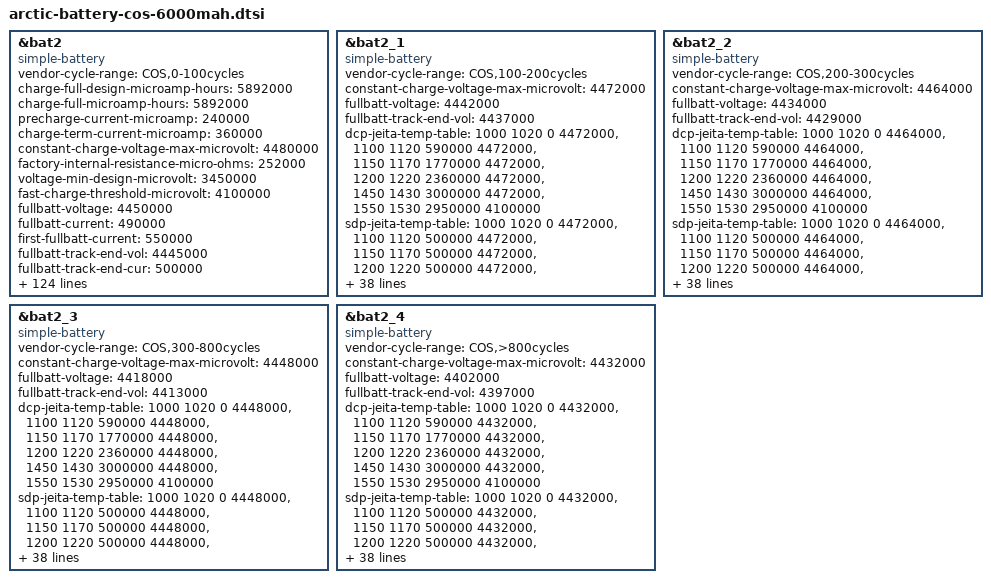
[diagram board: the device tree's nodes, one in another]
/* COS aging 0--100 */
&bat2 {
	compatible = "simple-battery";
	status = "okay";
	vendor-cycle-range = "COS,0-100cycles";
	charge-full-design-microamp-hours = <5892000>;
	charge-full-microamp-hours = <5892000>;
	precharge-current-microamp = <240000>;
	charge-term-current-microamp = <360000>;
	constant-charge-voltage-max-microvolt = <4480000>;
	factory-internal-resistance-micro-ohms = <252000>;
	voltage-min-design-microvolt = <3450000>;

	fast-charge-threshold-microvolt = <4100000>;
	fullbatt-voltage = <4450000>;
	fullbatt-current = <490000>;
	first-fullbatt-current = <550000>;
	fullbatt-track-end-vol = <4445000>;
	fullbatt-track-end-cur = <500000>;
	first-calib-voltage = <3580000>;
	first-calib-capacity = <50>;
	batt-ovp-threshold-microvolt = <4750000>;
	shutdown-voltage = <3150000>; //软件UVLO关机电压

	voltage-temp-table = <1119814 800>, <1007626 850>, <897107 900>,
				<791150 950>, <692012 1000>, <601214 1050>,
				<519546 1100>, <447188 1150>, <383853 1200>,
				<328947 1250>, <281696 1300>, <241249 1350>,
				<206756 1400>, <177412 1450>, <152480 1500>,
				<131307 1550>, <113324 1600>, <98032 1650>;

	temp-advance-fullcap-table = <50 100>, <25 100>, <10 100>, <0 100>,
		<(-10) 100>, <(-20) 100>;

	bcl-vbat-thres-celsius = <(-10)>, <0>, <10>, <25>, <45>;
	bcl-vbat-h-thres-0 = <3500>, <3400>;
	bcl-vbat-l-thres-0 = <3300>, <3200>;
	bcl-vbat-h-thres-1 = <3500>, <3400>;
	bcl-vbat-l-thres-1 = <3300>, <3200>;
	bcl-vbat-h-thres-2 = <3500>, <3400>;
	bcl-vbat-l-thres-2 = <3300>, <3200>;
	bcl-vbat-h-thres-3 = <3500>, <3400>;
	bcl-vbat-l-thres-3 = <3300>, <3200>;
	bcl-vbat-h-thres-4 = <3500>, <3400>;
	bcl-vbat-l-thres-4 = <3300>, <3200>;

	charge-sdp-current-microamp = <500000 500000>;
	charge-dcp-current-microamp = <2940000 1500000>;
	charge-cdp-current-microamp = <900000 900000>;
	charge-unknown-current-microamp = <1000000 1000000>;
	charge-fchg-current-microamp = <3000000 2000000>;
	charge-flash-current-microamp = <4900000 2700000>;
	charge-wl-bpp-current-microamp = <1000000 1000000>;
	charge-wl-epp-current-microamp = <2000000 1000000>;

	cap-calib-energy-density-ocv-table = <3400000 3690000>, <3895000 4480000>;

	dcp-jeita-temp-table = <1000 1020 0 4480000>, <1100 1120 590000 4480000>,
		<1150 1170 1770000 4480000>, <1200 1220 2360000 4480000>,
		<1450 1430 3000000 4480000>, <1550 1530 2950000 4100000>;
	sdp-jeita-temp-table = <1000 1020 0 4480000>, <1100 1120 500000 4480000>,
		<1150 1170 500000 4480000>, <1200 1220 500000 4480000>,
		<1450 1430 500000 4480000>, <1550 1530 500000 4100000>;
	cdp-jeita-temp-table = <1000 1020 0 4480000>, <1100 1120 590000 4480000>,
		<1150 1170 900000 4480000>, <1200 1220 900000 4480000>,
		<1450 1430 900000 4480000>, <1550 1530 900000 4100000>;
	unknown-jeita-temp-table = <1000 1020 0 4480000>, <1100 1120 590000 4480000>,
		<1150 1170 1000000 4480000>, <1200 1220 1000000 4480000>,
		<1450 1430 1000000 4480000>, <1550 1530 1000000 4100000>;
	fchg-jeita-temp-table = <1000 1020 0 4480000>, <1100 1120 590000 4480000>,
		<1150 1170 1770000 4480000>, <1200 1220 2360000 4480000>,
		<1450 1430 3000000 4480000>, <1550 1530 2950000 4100000>;
	flash-jeita-temp-table = <1000 1020 0 4480000>, <1100 1120 590000 4480000>,
		<1150 1170 1770000 4480000>, <1200 1220 2360000 4480000>,
		<1450 1430 3000000 4480000>, <1550 1530 2950000 4100000>;
	wl-bpp-jeita-temp-table = <1000 1020 0 4480000>, <1100 1120 500000 4480000>,
		<1150 1170 500000 4480000>, <1200 1220 500000 4480000>,
		<1450 1430 1000000 4480000>, <1550 1530 500000 4100000>;
	wl-epp-jeita-temp-table = <1000 1020 0 4480000>, <1100 1120 500000 4480000>,
		<1150 1170 500000 4480000>, <1200 1220 500000 4480000>,
		<1450 1430 2000000 4480000>, <1550 1530 500000 4100000>;


	bat-temp = <(-20)>, <(-10)>, <0>, <10>, <25>, <45>;

	/* temp-fcc */
	temp-fcc-fcc = <5456000>, <5701000>, <5768000>, <5817000>, <5892000>, <5811000>;

	/* temp-hc */
	temp-hc-hc = <30>, <20>, <20>, <10>, <10>, <10>;

	/* temp-zero-point-voltage */
	temp-zpvol-zpvol = <3430000>, <3430000>, <3430000>, <3450000>, <3450000>, <3450000>;
	/* temp-abs-zero-point-voltage */
	temp-abs-zpvol-zpvol = <3425000>, <3425000>, <3425000>, <3445000>, <3445000>, <3445000>;
	/* temp-bat-voltage */
	temp-batvol-batvol = <3570000>, <3570000>, <3570000>, <3580000>, <3580000>, <3580000>;

	/* cap-temp-ocv */
	cap-temp-ocv-cap = <100>, <99>, <98>, <97>, <96>, <95>, <94>, <93>, <92>, <91>, <90>,
			<89>, <88>, <87>, <86>, <85>, <84>, <83>, <82>, <81>, <80>,
			<79>, <78>, <77>, <76>, <75>, <74>, <73>, <72>, <71>, <70>,
			<69>, <68>, <67>, <66>, <65>, <64>, <63>, <62>, <61>, <60>,
			<59>, <58>, <57>, <56>, <55>, <54>, <53>, <52>, <51>, <50>,
			<49>, <48>, <47>, <46>, <45>, <44>, <43>, <42>, <41>, <40>,
			<39>, <38>, <37>, <36>, <35>, <34>, <33>, <32>, <31>, <30>,
			<29>, <28>, <27>, <26>, <25>, <24>, <23>, <22>, <21>, <20>,
			<19>, <18>, <17>, <16>, <15>, <14>, <13>, <12>, <11>, <10>,
			<9>, <8>, <7>, <6>, <5>, <4>, <3>, <2>, <1>, <0>;
	cap-temp-ocv-ocv = <
			/* -20 celsius */
			4416000 4391000 4371000 4353000 4337000 4322000 4308000 4294000 4282000 4269000
			4256000 4244000 4233000 4222000 4210000 4200000 4189000 4178000 4168000 4158000
			4148000 4138000 4128000 4118000 4108000 4098000 4087000 4076000 4066000 4056000
			4045000 4034000 4024000 4014000 4003000 3992000 3982000 3972000 3962000 3952000
			3943000 3934000 3924000 3916000 3907000 3898000 3890000 3882000 3875000 3868000
			3860000 3854000 3848000 3841000 3836000 3830000 3824000 3819000 3814000 3810000
			3806000 3802000 3798000 3794000 3792000 3788000 3785000 3782000 3778000 3775000
			3772000 3768000 3764000 3760000 3756000 3751000 3746000 3742000 3736000 3730000
			3724000 3718000 3711000 3704000 3696000 3688000 3678000 3669000 3658000 3648000
			3637000 3626000 3614000 3602000 3588000 3570000 3550000 3531000 3514000 3495000
			3473000
			/* -10 celsius */
			4424000 4402000 4384000 4370000 4356000 4343000 4331000 4318000 4306000 4293000
			4281000 4269000 4256000 4244000 4233000 4221000 4210000 4199000 4189000 4178000
			4168000 4158000 4148000 4137000 4127000 4116000 4106000 4095000 4085000 4074000
			4063000 4053000 4042000 4032000 4021000 4011000 4000000 3990000 3979000 3969000
			3958000 3948000 3937000 3927000 3917000 3907000 3898000 3888000 3880000 3872000
			3864000 3857000 3850000 3844000 3838000 3832000 3827000 3822000 3817000 3812000
			3808000 3803000 3799000 3796000 3793000 3790000 3787000 3784000 3782000 3780000
			3778000 3776000 3774000 3772000 3769000 3766000 3763000 3760000 3756000 3752000
			3748000 3742000 3736000 3729000 3720000 3710000 3698000 3683000 3666000 3646000
			3624000 3602000 3580000 3559000 3538000 3521000 3506000 3490000 3471000 3446000
			3400000
			/* 0 celsius */
			4416000 4398000 4384000 4370000 4357000 4344000 4332000 4319000 4306000 4294000
			4281000 4268000 4256000 4244000 4232000 4221000 4209000 4198000 4188000 4177000
			4167000 4156000 4146000 4135000 4124000 4114000 4103000 4092000 4082000 4071000
			4061000 4051000 4041000 4031000 4021000 4011000 4001000 3992000 3982000 3973000
			3963000 3953000 3943000 3932000 3921000 3909000 3898000 3888000 3879000 3870000
			3863000 3856000 3850000 3843000 3838000 3832000 3827000 3822000 3818000 3813000
			3809000 3805000 3802000 3798000 3795000 3792000 3789000 3786000 3784000 3782000
			3780000 3779000 3778000 3776000 3775000 3773000 3771000 3769000 3766000 3762000
			3758000 3753000 3748000 3742000 3736000 3727000 3716000 3704000 3686000 3663000
			3636000 3608000 3582000 3560000 3542000 3526000 3509000 3491000 3472000 3446000
			3400000
			/* 10 celsius */
			4418000 4402000 4388000 4374000 4362000 4348000 4336000 4324000 4310000 4298000
			4286000 4272000 4260000 4248000 4236000 4225000 4214000 4202000 4192000 4182000
			4170000 4160000 4148000 4138000 4127000 4116000 4106000 4094000 4084000 4074000
			4064000 4054000 4043000 4033000 4024000 4014000 4004000 3995000 3986000 3976000
			3967000 3957000 3947000 3936000 3926000 3914000 3902000 3891000 3882000 3874000
			3866000 3858000 3852000 3846000 3840000 3836000 3830000 3826000 3822000 3818000
			3814000 3810000 3806000 3802000 3798000 3796000 3794000 3790000 3788000 3786000
			3784000 3782000 3781000 3780000 3778000 3776000 3774000 3771000 3768000 3764000
			3760000 3754000 3750000 3746000 3742000 3735000 3727000 3718000 3708000 3696000
			3680000 3658000 3630000 3602000 3580000 3560000 3542000 3524000 3502000 3462000
			3400000
			/* 25 celsius */
			4428000 4409000 4393000 4378000 4364000 4350000 4338000 4324000 4312000 4299000
			4286000 4274000 4260000 4248000 4236000 4224000 4213000 4202000 4190000 4180000
			4169000 4158000 4147000 4136000 4125000 4114000 4103000 4092000 4082000 4071000
			4061000 4050000 4040000 4030000 4020000 4011000 4001000 3992000 3983000 3974000
			3966000 3957000 3948000 3938000 3928000 3917000 3904000 3892000 3880000 3871000
			3863000 3856000 3850000 3844000 3838000 3833000 3828000 3824000 3819000 3814000
			3810000 3806000 3804000 3800000 3796000 3794000 3790000 3788000 3786000 3784000
			3782000 3780000 3777000 3774000 3772000 3768000 3764000 3760000 3758000 3754000
			3750000 3746000 3742000 3739000 3734000 3730000 3722000 3716000 3710000 3702000
			3694000 3687000 3682000 3674000 3659000 3632000 3602000 3570000 3531000 3474000
			3400000
			/* 45 celsius */
			4410000 4394000 4380000 4366000 4352000 4340000 4327000 4314000 4302000 4289000
			4276000 4264000 4252000 4240000 4230000 4218000 4207000 4197000 4186000 4176000
			4165000 4154000 4144000 4133000 4122000 4112000 4101000 4090000 4080000 4070000
			4060000 4049000 4040000 4030000 4020000 4011000 4002000 3992000 3984000 3976000
			3966000 3958000 3950000 3940000 3929000 3917000 3904000 3892000 3884000 3876000
			3868000 3862000 3856000 3850000 3845000 3840000 3835000 3830000 3826000 3821000
			3817000 3814000 3810000 3806000 3803000 3800000 3797000 3794000 3791000 3789000
			3786000 3784000 3781000 3776000 3770000 3764000 3760000 3756000 3752000 3748000
			3744000 3741000 3738000 3734000 3729000 3724000 3718000 3711000 3705000 3698000
			3689000 3685000 3682000 3676000 3667000 3648000 3619000 3584000 3538000 3476000
			3400000
			>;


	/* cap-temp-resist */
	cap-temp-resist-cap = <100>, <99>, <98>, <97>, <96>, <95>, <94>, <93>, <92>, <91>, <90>,
			<89>, <88>, <87>, <86>, <85>, <84>, <83>, <82>, <81>, <80>,
			<79>, <78>, <77>, <76>, <75>, <74>, <73>, <72>, <71>, <70>,
			<69>, <68>, <67>, <66>, <65>, <64>, <63>, <62>, <61>, <60>,
			<59>, <58>, <57>, <56>, <55>, <54>, <53>, <52>, <51>, <50>,
			<49>, <48>, <47>, <46>, <45>, <44>, <43>, <42>, <41>, <40>,
			<39>, <38>, <37>, <36>, <35>, <34>, <33>, <32>, <31>, <30>,
			<29>, <28>, <27>, <26>, <25>, <24>, <23>, <22>, <21>, <20>,
			<19>, <18>, <17>, <16>, <15>, <14>, <13>, <12>, <11>, <10>,
			<9>, <8>, <7>, <6>, <5>, <4>, <3>, <2>, <1>, <0>;
	cap-temp-resist-resist = <
		  /* -20 celsius m o */
			834  834  832  831  826  820  812  804  796  790
			784  776  771  763  756  750  745  739  734  730
			725  722  718  715  712  709  706  703  700  697
			695  694  691  689  686  684  682  680  680  678
			677  676  676  674  674  674  675  676  676  678
			680  683  686  689  693  696  700  704  710  714
			722  728  735  744  754  764  776  788  801  814
			831  848  866  884  904  924  944  966  988 1010
			1032 1056 1080 1108 1139 1173 1216 1270 1342 1442
			1584 1808 2176 2626 2734 2734 2734 2734 2734 2734
			2734
		  /* -10 celsius */
			382  382  384  381  378  375  371  367  364  359
			355  350  346  343  339  336  333  330  328  325
			323  320  320  318  318  318  317  317  316  316
			316  316  318  317  316  314  314  312  310  307
			304  301  299  296  292  290  288  286  283  282
			282  282  282  282  282  283  285  286  288  291
			294  295  298  300  302  306  310  314  318  324
			330  336  344  353  364  375  386  398  410  423
			437  451  466  482  500  518  539  560  583  612
			652  716  839 1132 1816 2564 2564 2564 2564 2564
			2564
		  /* 0 celsius */
			184  184  184  182  180  179  178  177  176  175
			173  172  171  170  170  170  169  169  168  168
			168  168  168  168  170  170  171  171  172  174
			175  176  178  179  180  182  183  184  185  186
			186  184  182  178  174  168  163  159  156  154
			152  152  152  151  152  152  152  152  154  154
			155  156  157  158  158  160  160  162  164  165
			166  168  170  172  176  178  182  184  188  191
			195  198  204  212  222  236  254  276  298  314
			322  326  336  358  403  520  954 2010 2444 2444
			2444
		  /* 10 celsius */
			130 130 130 128 128 126 126 126 124 124
			124 122 122 122 122 122 121 121 121 121
			120 120 121 121 121 122 122 123 123 125
			126 126 128 130 130 133 135 136 138 139
			140 140 140 138 134 129 123 118 114 113
			112 112 111 111 111 110 111 111 112 112
			113 113 114 115 115 116 116 116 118 119
			119 120 120 122 123 123 124 124 123 124
			124 124 127 129 131 135 138 145 153 164
			180 192 196 194 194 198 208 226 264 357
			703
		  /* 25 celsius */
			86  86  86  86  85  85  84  84  84  84
			82  83  82  82  82  82  82  82  82  82
			82  82  82  82  82  82  82  82  84  84
			84  85  86  88  88  88  90  90  92  94
			95  97  98  99 100  98  92  85  82  80
			80  78  78  78  78  78  78  80  80  80
			80  81  81  82  82  82  83  84  84  84
			85  86  86  86  84  82  80  80  80  80
			80  80  81  82  82  82  82  83  84  84
			85  88  92  94 100 106 109 108 107 106
			110
		  /* 45 celsius */
			75 75 75 75 74 74 74 73 74 74
			74 73 74 73 74 73 73 73 73 73
			72 72 72 74 74 73 74 74 74 74
			74 74 76 76 76 77 78 78 80 80
			82 84 84 86 84 82 76 73 72 72
			72 72 72 72 72 71 72 72 72 72
			72 72 73 73 73 74 74 75 75 76
			77 78 77 74 71 70 71 71 71 71
			71 71 72 72 72 72 72 72 72 74
			74 76 76 76 78 82 85 86 85 86
			89
		>;
	cap-temp-resist-cycle = <300>, <600>;
	cap-temp-resist-ratio-0 = <
		  /* -20 celsius m o */
		  1030 1030 1030 1030 1030 1030 1030 1030 1030 1030 1040
		  1050 1050 1050 1060 1060 1060 1060 1060 1060 1060 1060
		  1060 1060 1060 1060 1060 1060 1060 1060 1060 1060 1060
		  1060 1060 1060 1060 1060 1060 1060 1060 1060 1060 1060
		  1060 1060 1060 1060 1060 1060 1060 1060 1060 1060 1060
		  1060 1060 1060 1060 1060 1060 1060 1060 1060 1050 1050
		  1050 1050 1050 1050 1050 1050 1050 1050 1050 1050 1050
		  1050 1050 1050 1050 1050 1050 1050 1050 1050 1050 1050
		  1050 1050 1050 1050 1050 1050 1050 1050 1050 1050 1050
		  1050 1050
		  /* -10 celsius */
		  1050 1050 1050 1050 1050 1050 1050 1050 1050 1050 1050
		  1050 1050 1050 1050 1050 1050 1050 1050 1050 1050 1050
		  1050 1050 1050 1050 1050 1050 1050 1050 1050 1050 1050
		  1050 1050 1050 1050 1050 1050 1050 1050 1050 1050 1050
		  1050 1050 1050 1050 1050 1050 1050 1050 1050 1050 1050
		  1050 1050 1050 1050 1050 1050 1050 1050 1050 1050 1050
		  1050 1050 1050 1050 1050 1050 1050 1050 1050 1050 1050
		  1050 1050 1050 1050 1050 1050 1050 1050 1050 1050 1050
		  1050 1050 1050 1050 1050 1050 1050 1050 1050 1050 1050
		  1050 1050
		  /* 0 celsius */
		  1160 1160 1160 1160 1160 1160 1160 1160 1170 1170 1170
		  1170 1170 1170 1170 1170 1170 1170 1170 1170 1170 1170
		  1170 1170 1170 1170 1170 1170 1170 1170 1170 1170 1170
		  1170 1170 1170 1180 1180 1180 1180 1180 1180 1180 1180
		  1180 1180 1190 1190 1190 1190 1190 1190 1190 1190 1190
		  1190 1190 1190 1190 1190 1190 1190 1190 1190 1190 1190
		  1190 1200 1200 1210 1220 1220 1220 1220 1220 1220 1230
		  1230 1230 1230 1230 1230 1230 1230 1230 1230 1230 1230
		  1230 1230 1230 1230 1250 1270 1290 1320 1350 1370 1400
		  1430 1430
		  /* 10 celsius */
		  1270 1270 1270 1270 1270 1270 1270 1270 1270 1280 1280
		  1280 1280 1290 1290 1290 1290 1290 1290 1290 1290 1290
		  1290 1300 1300 1300 1300 1300 1300 1300 1300 1300 1300
		  1300 1310 1310 1310 1310 1310 1310 1310 1310 1310 1310
		  1320 1320 1320 1320 1320 1320 1320 1320 1320 1320 1320
		  1320 1320 1330 1330 1330 1330 1330 1330 1330 1330 1330
		  1330 1330 1330 1330 1340 1340 1340 1340 1340 1340 1350
		  1360 1380 1400 1410 1430 1450 1470 1490 1500 1510 1520
		  1530 1530 1530 1530 1530 1530 1530 1530 1530 1530 1530
		  1530 1530
		  /* 25 celsius */
		  1110 1110 1110 1110 1110 1110 1110 1120 1120 1120 1130
		  1130 1140 1140 1140 1140 1140 1130 1130 1130 1130 1130
		  1130 1120 1120 1120 1120 1120 1120 1120 1120 1120 1120
		  1130 1130 1130 1130 1130 1140 1140 1140 1140 1140 1150
		  1150 1160 1160 1160 1160 1160 1160 1160 1160 1150 1150
		  1150 1150 1150 1160 1160 1160 1160 1160 1160 1150 1150
		  1150 1150 1150 1160 1160 1160 1160 1160 1160 1160 1160
		  1160 1160 1160 1160 1160 1160 1160 1160 1160 1150 1150
		  1150 1150 1150 1150 1150 1160 1160 1160 1160 1160 1160
		  1160 1160
		  /* 45 celsius */
		  1260 1260 1260 1260 1260 1260 1260 1270 1280 1290 1300
		  1300 1300 1300 1300 1300 1300 1300 1300 1300 1300 1300
		  1290 1290 1280 1270 1280 1290 1300 1310 1310 1310 1310
		  1310 1310 1310 1310 1310 1310 1310 1310 1310 1300 1290
		  1280 1270 1270 1270 1270 1270 1290 1290 1290 1290 1300
		  1310 1310 1310 1310 1310 1310 1310 1310 1300 1290 1290
		  1290 1290 1290 1300 1310 1310 1320 1320 1320 1320 1320
		  1320 1320 1320 1320 1320 1320 1320 1320 1320 1320 1310
		  1310 1310 1310 1310 1310 1310 1310 1320 1320 1320 1320
		  1320 1320
		>;

	cap-temp-resist-ratio-1 = <
		  /* -20 celsius m o */
		  1160 1160 1160 1160 1160 1160 1160 1160 1160 1170 1170
		  1180 1180 1190 1190 1190 1190 1200 1200 1210 1210 1210
		  1220 1220 1230 1230 1240 1250 1260 1270 1270 1270 1280
		  1290 1300 1310 1320 1340 1360 1380 1400 1400 1430 1460
		  1490 1520 1520 1520 1550 1590 1630 1660 1660 1690 1720
		  1750 1770 1770 1770 1770 1770 1770 1770 1770 1770 1770
		  1770 1770 1770 1770 1770 1770 1770 1770 1770 1770 1770
		  1770 1770 1770 1770 1770 1770 1770 1770 1770 1770 1770
		  1770 1770 1770 1770 1770 1770 1770 1770 1770 1770 1770
		  1770 1770
		  /* -10 celsius */
		  1180 1180 1180 1180 1180 1180 1180 1180 1170 1170 1170
		  1170 1170 1170 1170 1170 1170 1170 1170 1170 1170 1170
		  1170 1170 1170 1170 1170 1170 1170 1170 1170 1170 1170
		  1170 1170 1170 1170 1170 1170 1170 1170 1170 1170 1190
		  1190 1190 1190 1190 1200 1200 1200 1200 1200 1210 1210
		  1210 1210 1210 1210 1220 1240 1250 1270 1290 1290 1290
		  1290 1290 1290 1290 1300 1310 1320 1330 1340 1350 1350
		  1350 1370 1390 1410 1420 1440 1440 1460 1480 1500 1530
		  1550 1570 1590 1610 1620 1620 1620 1620 1620 1620 1620
		  1620 1620
		  /* 0 celsius */
		  1420 1420 1420 1420 1420 1420 1420 1420 1410 1410 1410
		  1410 1410 1410 1410 1410 1410 1410 1410 1410 1410 1410
		  1400 1400 1400 1400 1400 1400 1400 1400 1400 1400 1400
		  1400 1400 1400 1400 1400 1400 1400 1400 1400 1410 1410
		  1410 1410 1420 1420 1420 1420 1420 1420 1420 1420 1420
		  1420 1430 1430 1430 1430 1430 1430 1450 1450 1450 1450
		  1450 1450 1500 1500 1500 1500 1500 1500 1530 1530 1530
		  1530 1530 1530 1550 1550 1550 1550 1610 1610 1610 1610
		  1650 1700 1750 1800 1850 1900 1900 1900 1900 1900 1900
		  1900 1900
		  /* 10 celsius */
		  1400 1400 1400 1400 1400 1400 1400 1400 1400 1420 1420
		  1420 1420 1420 1420 1420 1420 1420 1420 1420 1420 1420
		  1420 1420 1420 1420 1420 1420 1410 1410 1410 1410 1410
		  1410 1410 1410 1410 1410 1410 1410 1410 1410 1410 1410
		  1410 1420 1420 1420 1420 1430 1430 1430 1430 1430 1420
		  1430 1430 1430 1430 1430 1430 1430 1430 1430 1430 1430
		  1430 1430 1430 1430 1470 1470 1470 1470 1470 1530 1530
		  1530 1530 1530 1590 1590 1590 1590 1630 1680 1710 1710
		  1780 1840 1900 1950 2000 2050 2100 2150 2200 2250 2250
		  2250 2250
		  /* 25 celsius */
		  1320 1320 1320 1320 1320 1320 1320 1320 1320 1320 1320
		  1320 1310 1310 1310 1310 1310 1310 1300 1300 1300 1300
		  1300 1290 1290 1290 1290 1290 1280 1280 1280 1280 1280
		  1280 1280 1280 1280 1280 1280 1280 1280 1280 1280 1290
		  1290 1300 1310 1310 1310 1310 1310 1310 1310 1310 1310
		  1310 1310 1310 1310 1310 1310 1310 1310 1310 1310 1310
		  1310 1310 1310 1310 1310 1310 1310 1320 1330 1340 1350
		  1350 1360 1360 1360 1360 1360 1370 1370 1370 1380 1390
		  1400 1410 1420 1430 1450 1460 1460 1460 1460 1460 1460
		  1460 1460
		  /* 45 celsius */
		  1298 1298 1298 1298 1298 1298 1298 1308 1318 1329 1339
		  1339 1339 1339 1339 1339 1339 1339 1339 1339 1339 1339
		  1329 1329 1318 1308 1318 1329 1339 1349 1349 1349 1349
		  1349 1349 1349 1349 1349 1349 1349 1349 1349 1339 1329
		  1318 1308 1308 1308 1308 1308 1329 1329 1329 1329 1339
		  1349 1349 1349 1349 1349 1349 1349 1349 1339 1329 1329
		  1329 1329 1329 1339 1349 1349 1360 1360 1360 1360 1360
		  1360 1360 1360 1360 1360 1360 1360 1360 1360 1360 1349
		  1349 1349 1349 1349 1349 1349 1349 1360 1360 1360 1360
		  1360 1360
		>;
};

/* COS aging 100--200 */
&bat2_1 {
	compatible = "simple-battery";
	status = "okay";
	vendor-cycle-range = "COS,100-200cycles";
	constant-charge-voltage-max-microvolt = <4472000>;
	fullbatt-voltage = <4442000>;
	fullbatt-track-end-vol = <4437000>;

	dcp-jeita-temp-table = <1000 1020 0 4472000>, <1100 1120 590000 4472000>,
		<1150 1170 1770000 4472000>, <1200 1220 2360000 4472000>,
		<1450 1430 3000000 4472000>, <1550 1530 2950000 4100000>;
	sdp-jeita-temp-table = <1000 1020 0 4472000>, <1100 1120 500000 4472000>,
		<1150 1170 500000 4472000>, <1200 1220 500000 4472000>,
		<1450 1430 500000 4472000>, <1550 1530 500000 4100000>;
	cdp-jeita-temp-table = <1000 1020 0 4472000>, <1100 1120 590000 4472000>,
		<1150 1170 900000 4472000>, <1200 1220 900000 4472000>,
		<1450 1430 900000 4472000>, <1550 1530 900000 4100000>;
	unknown-jeita-temp-table = <1000 1020 0 4472000>, <1100 1120 590000 4472000>,
		<1150 1170 1000000 4472000>, <1200 1220 1000000 4472000>,
		<1450 1430 1000000 4472000>, <1550 1530 1000000 4100000>;
	fchg-jeita-temp-table = <1000 1020 0 4472000>, <1100 1120 590000 4472000>,
		<1150 1170 1770000 4472000>, <1200 1220 2360000 4472000>,
		<1450 1430 3000000 4472000>, <1550 1530 2950000 4100000>;
	flash-jeita-temp-table = <1000 1020 0 4472000>, <1100 1120 590000 4472000>,
		<1150 1170 1770000 4472000>, <1200 1220 2360000 4472000>,
		<1450 1430 3000000 4472000>, <1550 1530 2950000 4100000>;
	wl-bpp-jeita-temp-table = <1000 1020 0 4472000>, <1100 1120 500000 4472000>,
		<1150 1170 500000 4472000>, <1200 1220 500000 4472000>,
		<1450 1430 1000000 4472000>, <1550 1530 500000 4100000>;
	wl-epp-jeita-temp-table = <1000 1020 0 4472000>, <1100 1120 500000 4472000>,
		<1150 1170 500000 4472000>, <1200 1220 500000 4472000>,
		<1450 1430 2000000 4472000>, <1550 1530 500000 4100000>;
};

/* COS aging 200--300 */
&bat2_2 {
	compatible = "simple-battery";
	status = "okay";
	vendor-cycle-range = "COS,200-300cycles";
	constant-charge-voltage-max-microvolt = <4464000>;
	fullbatt-voltage = <4434000>;
	fullbatt-track-end-vol = <4429000>;

	dcp-jeita-temp-table = <1000 1020 0 4464000>, <1100 1120 590000 4464000>,
		<1150 1170 1770000 4464000>, <1200 1220 2360000 4464000>,
		<1450 1430 3000000 4464000>, <1550 1530 2950000 4100000>;
	sdp-jeita-temp-table = <1000 1020 0 4464000>, <1100 1120 500000 4464000>,
		<1150 1170 500000 4464000>, <1200 1220 500000 4464000>,
		<1450 1430 500000 4464000>, <1550 1530 500000 4100000>;
	cdp-jeita-temp-table = <1000 1020 0 4464000>, <1100 1120 590000 4464000>,
		<1150 1170 900000 4464000>, <1200 1220 900000 4464000>,
		<1450 1430 900000 4464000>, <1550 1530 900000 4100000>;
	unknown-jeita-temp-table = <1000 1020 0 4464000>, <1100 1120 590000 4464000>,
		<1150 1170 1000000 4464000>, <1200 1220 1000000 4464000>,
		<1450 1430 1000000 4464000>, <1550 1530 1000000 4100000>;
	fchg-jeita-temp-table = <1000 1020 0 4464000>, <1100 1120 590000 4464000>,
		<1150 1170 1770000 4464000>, <1200 1220 2360000 4464000>,
		<1450 1430 3000000 4464000>, <1550 1530 2950000 4100000>;
	flash-jeita-temp-table = <1000 1020 0 4464000>, <1100 1120 590000 4464000>,
		<1150 1170 1770000 4464000>, <1200 1220 2360000 4464000>,
		<1450 1430 3000000 4464000>, <1550 1530 2950000 4100000>;
	wl-bpp-jeita-temp-table = <1000 1020 0 4464000>, <1100 1120 500000 4464000>,
		<1150 1170 500000 4464000>, <1200 1220 500000 4464000>,
		<1450 1430 1000000 4464000>, <1550 1530 500000 4100000>;
	wl-epp-jeita-temp-table = <1000 1020 0 4464000>, <1100 1120 500000 4464000>,
		<1150 1170 500000 4464000>, <1200 1220 500000 4464000>,
		<1450 1430 2000000 4464000>, <1550 1530 500000 4100000>;
};

/* COS aging 300--800 */
&bat2_3 {
	compatible = "simple-battery";
	status = "okay";
	vendor-cycle-range = "COS,300-800cycles";
	constant-charge-voltage-max-microvolt = <4448000>;
	fullbatt-voltage = <4418000>;
	fullbatt-track-end-vol = <4413000>;

	dcp-jeita-temp-table = <1000 1020 0 4448000>, <1100 1120 590000 4448000>,
		<1150 1170 1770000 4448000>, <1200 1220 2360000 4448000>,
		<1450 1430 3000000 4448000>, <1550 1530 2950000 4100000>;
	sdp-jeita-temp-table = <1000 1020 0 4448000>, <1100 1120 500000 4448000>,
		<1150 1170 500000 4448000>, <1200 1220 500000 4448000>,
		<1450 1430 500000 4448000>, <1550 1530 500000 4100000>;
	cdp-jeita-temp-table = <1000 1020 0 4448000>, <1100 1120 590000 4448000>,
		<1150 1170 900000 4448000>, <1200 1220 900000 4448000>,
		<1450 1430 900000 4448000>, <1550 1530 900000 4100000>;
	unknown-jeita-temp-table = <1000 1020 0 4448000>, <1100 1120 590000 4448000>,
		<1150 1170 1000000 4448000>, <1200 1220 1000000 4448000>,
		<1450 1430 1000000 4448000>, <1550 1530 1000000 4100000>;
	fchg-jeita-temp-table = <1000 1020 0 4448000>, <1100 1120 590000 4448000>,
		<1150 1170 1770000 4448000>, <1200 1220 2360000 4448000>,
		<1450 1430 3000000 4448000>, <1550 1530 2950000 4100000>;
	flash-jeita-temp-table = <1000 1020 0 4448000>, <1100 1120 590000 4448000>,
		<1150 1170 1770000 4448000>, <1200 1220 2360000 4448000>,
		<1450 1430 3000000 4448000>, <1550 1530 2950000 4100000>;
	wl-bpp-jeita-temp-table = <1000 1020 0 4448000>, <1100 1120 500000 4448000>,
		<1150 1170 500000 4448000>, <1200 1220 500000 4448000>,
		<1450 1430 1000000 4448000>, <1550 1530 500000 4100000>;
	wl-epp-jeita-temp-table = <1000 1020 0 4448000>, <1100 1120 500000 4448000>,
		<1150 1170 500000 4448000>, <1200 1220 500000 4448000>,
		<1450 1430 2000000 4448000>, <1550 1530 500000 4100000>;
};

/* COS aging > 800 */
&bat2_4 {
	compatible = "simple-battery";
	status = "okay";
	vendor-cycle-range = "COS,>800cycles";
	constant-charge-voltage-max-microvolt = <4432000>;
	fullbatt-voltage = <4402000>;
	fullbatt-track-end-vol = <4397000>;

	dcp-jeita-temp-table = <1000 1020 0 4432000>, <1100 1120 590000 4432000>,
		<1150 1170 1770000 4432000>, <1200 1220 2360000 4432000>,
		<1450 1430 3000000 4432000>, <1550 1530 2950000 4100000>;
	sdp-jeita-temp-table = <1000 1020 0 4432000>, <1100 1120 500000 4432000>,
		<1150 1170 500000 4432000>, <1200 1220 500000 4432000>,
		<1450 1430 500000 4432000>, <1550 1530 500000 4100000>;
	cdp-jeita-temp-table = <1000 1020 0 4432000>, <1100 1120 590000 4432000>,
		<1150 1170 900000 4432000>, <1200 1220 900000 4432000>,
		<1450 1430 900000 4432000>, <1550 1530 900000 4100000>;
	unknown-jeita-temp-table = <1000 1020 0 4432000>, <1100 1120 590000 4432000>,
		<1150 1170 1000000 4432000>, <1200 1220 1000000 4432000>,
		<1450 1430 1000000 4432000>, <1550 1530 1000000 4100000>;
	fchg-jeita-temp-table = <1000 1020 0 4432000>, <1100 1120 590000 4432000>,
		<1150 1170 1770000 4432000>, <1200 1220 2360000 4432000>,
		<1450 1430 3000000 4432000>, <1550 1530 2950000 4100000>;
	flash-jeita-temp-table = <1000 1020 0 4432000>, <1100 1120 590000 4432000>,
		<1150 1170 1770000 4432000>, <1200 1220 2360000 4432000>,
		<1450 1430 3000000 4432000>, <1550 1530 2950000 4100000>;
	wl-bpp-jeita-temp-table = <1000 1020 0 4432000>, <1100 1120 500000 4432000>,
		<1150 1170 500000 4432000>, <1200 1220 500000 4432000>,
		<1450 1430 1000000 4432000>, <1550 1530 500000 4100000>;
	wl-epp-jeita-temp-table = <1000 1020 0 4432000>, <1100 1120 500000 4432000>,
		<1150 1170 500000 4432000>, <1200 1220 500000 4432000>,
		<1450 1430 2000000 4432000>, <1550 1530 500000 4100000>;
};
